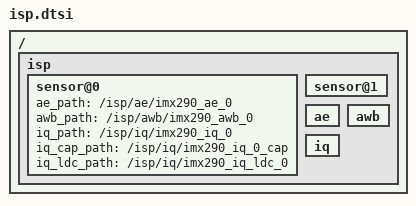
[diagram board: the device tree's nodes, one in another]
/ {
	isp {
		sensor@0 {
			ae_path                 = "/isp/ae/imx290_ae_0";
			awb_path                = "/isp/awb/imx290_awb_0";
			iq_path                 = "/isp/iq/imx290_iq_0";
			iq_cap_path				= "/isp/iq/imx290_iq_0_cap";
			iq_ldc_path				="/isp/iq/imx290_iq_ldc_0";
		};
		sensor@1 {
		};
		/* label for ae, awb, iq table */
		ae: ae {
		};
		awb: awb {
		};
		iq: iq {
		};
	};
};


/*#include "iq_off_iq_ldc.dtsi"*/

/* Note: put include files in the tail since label should be declared first. */
#include "imx290_ae_0.dtsi"
#include "imx290_awb_0.dtsi"
#include "imx290_iq_0.dtsi"
#include "imx290_iq_0.dtsi"
#include "imx290_iq_ldc_0.dtsi"

